VERSION ""

NS_ :

BS_:

BU_: XXX

BO_ 35 EPS_1: 8 XXX
 SG_ STEER_ANGLE : 7|16@0+ (0.5,-2048) [0|65535] "degs" XXX
 SG_ TORQUE_MOTOR : 23|16@0+ (1,-4096) [0|65535] "" XXX
 SG_ COUNTER : 55|4@0+ (1,0) [0|15] "" XXX
 SG_ CHECKSUM : 63|8@0+ (1,0) [0|255] "" XXX

BO_ 37 PCM_1: 8 XXX
 SG_ ENGINE_RPM : 7|16@0+ (1,0) [0|1] "" XXX
 SG_ ENGINE_TRQ_REQ : 23|12@0+ (1,0) [0|1] "" XXX
 SG_ COUNTER : 55|4@0+ (1,0) [0|15] "" XXX
 SG_ CHECKSUM : 63|8@0+ (1,0) [0|255] "" XXX

BO_ 49 EPS_2: 8 XXX
 SG_ STEER_RATE_DRIVER : 19|12@0+ (0.125,-256) [0|1] "degs/s" XXX
 SG_ TORQUE_DRIVER : 35|12@0+ (1,-1024) [-1024|1024] "" XXX
 SG_ EPS_STATUS : 39|4@0+ (1,0) [0|15] "" XXX
 SG_ CHECKSUM : 63|8@0+ (1,0) [0|255] "" XXX
 SG_ COUNTER : 55|4@0+ (1,0) [0|15] "" XXX

BO_ 53 PCM_2: 8 XXX
 SG_ ENG_TORQUE_REQ : 3|12@0+ (1,0) [0|7] "" XXX
 SG_ ENG_TORQUE_OUT : 19|12@0+ (1,0) [0|1] "" XXX
 SG_ CHECKSUM : 63|8@0+ (1,0) [0|255] "" XXX
 SG_ COUNTER : 55|4@0+ (1,0) [0|15] "" XXX

BO_ 121 ABS_1: 8 XXX
 SG_ BRK_PRESSURE : 3|12@0+ (1,0) [0|1] "" XXX
 SG_ BRAKE_PEDAL : 19|12@0+ (1,0) [0|1] "" XXX
 SG_ COUNTER : 55|4@0+ (1,0) [0|15] "" XXX
 SG_ CHECKSUM : 63|8@0+ (1,0) [0|255] "" XXX

BO_ 129 TPS_1: 8 XXX
 SG_ THROTTLE_POSITION : 47|8@0+ (0.5,0) [0|255] "%" XXX

BO_ 133 TCM_1: 8 XXX
 SG_ DESIRED_GEAR : 15|4@0+ (1,0) [0|1] "" XXX
 SG_ SHIFT_PENDING : 2|1@0+ (1,0) [0|1] "" XXX
 SG_ SPEED_TURBINE : 27|12@0+ (0.04,0) [0|1] "km/h" XXX
 SG_ ACTUAL_GEAR : 11|4@0+ (1,0) [0|15] "" XXX

BO_ 135 ABS_2: 8 XXX
 SG_ COUNTER : 55|4@0+ (1,0) [0|1] "" XXX
 SG_ CHECKSUM : 63|8@0+ (1,0) [0|1] "" XXX
 SG_ DRIVER_BRAKE : 15|8@0+ (1,0) [0|1] "" XXX

BO_ 139 WHEEL_SPEEDS: 8 XXX
 SG_ WHEEL_SPEED_LR : 3|12@0+ (0.02,0) [0|4095] "" XXX
 SG_ WHEEL_SPEED_RR : 19|12@0+ (0.02,0) [0|4095] "" XXX
 SG_ WHEEL_SPEED_LF : 35|12@0+ (0.02,0) [0|4095] "" XXX
 SG_ WHEEL_SPEED_RF : 51|12@0+ (0.02,0) [0|4095] "" XXX

BO_ 153 FORWARD_CAMERA_ACC: 8 XXX
 SG_ ACC_ENG_TRQ_REQ : 3|8@0+ (1,0) [0|1] "" XXX
 SG_ ACC_GAS_CONTROL : 7|1@0+ (1,0) [0|1] "" XXX
 SG_ ACC_STATUS : 21|2@0+ (1,0) [0|3] "" XXX
 SG_ COUNTER : 55|4@0+ (1,0) [0|15] "" XXX
 SG_ CHECKSUM : 63|8@0+ (1,0) [0|255] "" XXX

BO_ 163 FORWARD_CAMERA_CLUSTER: 8 XXX
 SG_ ACC_SET_SPEED : 31|8@0+ (1,0) [0|255] "km/h" XXX

BO_ 166 FORWARD_CAMERA_LKAS: 8 XXX
 SG_ LKAS_COMMAND : 15|16@0+ (1,-1024) [0|4095] "" XXX
 SG_ LKAS_CONTROL_BIT : 25|1@0+ (1,0) [0|1] "" XXX
 SG_ COUNTER : 55|4@0+ (1,0) [0|15] "" XXX
 SG_ CHECKSUM : 63|8@0+ (1,0) [0|255] "" XXX

BO_ 173 SHIFTER_ASSM: 8 XXX
 SG_ SHIFTER_POSITION : 3|4@0+ (1,0) [0|15] "" XXX
 SG_ COUNTER : 31|4@0+ (1,0) [0|15] "" XXX
 SG_ CHECKSUM : 39|8@0+ (1,0) [0|255] "" XXX

BO_ 177 WHEEL_BUTTONS_CRUISE_CONTROL: 8 XXX
 SG_ CANCEL : 0|1@0+ (1,0) [0|3] "" XXX
 SG_ SET_PLUS : 2|1@0+ (1,0) [0|1] "" XXX
 SG_ SET_MINUS : 3|1@0+ (1,0) [0|3] "" XXX
 SG_ RESUME : 4|1@0+ (1,0) [0|1] "" XXX
 SG_ CRUISE_CONTROL : 6|1@0+ (1,0) [0|1] "" XXX
 SG_ COUNTER : 15|4@0+ (1,0) [0|15] "" XXX
 SG_ CHECKSUM : 23|8@0+ (1,0) [0|255] "" XXX

BO_ 221 CENTER_STACK: 8 XXX
 SG_ TRAC_OFF : 54|1@0+ (1,0) [0|1] "" XXX

BO_ 250 FORWARD_CAMERA_HUD: 8 XXX
 SG_ AUTO_HIGH_BEAM_BIT : 47|1@0+ (1,0) [0|1] "" XXX
 SG_ LKAS_HUD : 11|4@0+ (1,0) [0|15] "" XXX

BO_ 464 OCCUPANT_RESTRAINT_MODULE: 8 XXX
 SG_ DRIVER_SEATBELT_STATUS : 16|1@0+ (1,0) [0|1] "" XXX

BO_ 657 DOORS: 8 XXX
 SG_ DOOR_OPEN_LF : 17|1@0+ (1,0) [0|1] "" XXX
 SG_ DOOR_OPEN_RF : 18|1@1+ (1,0) [0|3] "" XXX
 SG_ DOOR_OPEN_LR : 19|1@0+ (1,0) [0|1] "" XXX
 SG_ DOOR_OPEN_RR : 20|1@0+ (1,0) [0|1] "" XXX

BO_ 792 STEERING_LEVERS: 8 XXX
 SG_ BLINKER_LEFT : 0|1@0+ (1,0) [0|3] "" XXX
 SG_ BLINKER_RIGHT : 1|1@0+ (1,0) [0|1] "" XXX
 SG_ HIGH_BEAM_FLASH : 3|1@0+ (1,0) [0|3] "" XXX
 SG_ AUTO_HIGH_BEAM : 2|1@0+ (1,0) [0|1] "" XXX

BO_ 232 ACC_CAR_DETECTED: 8 XXX

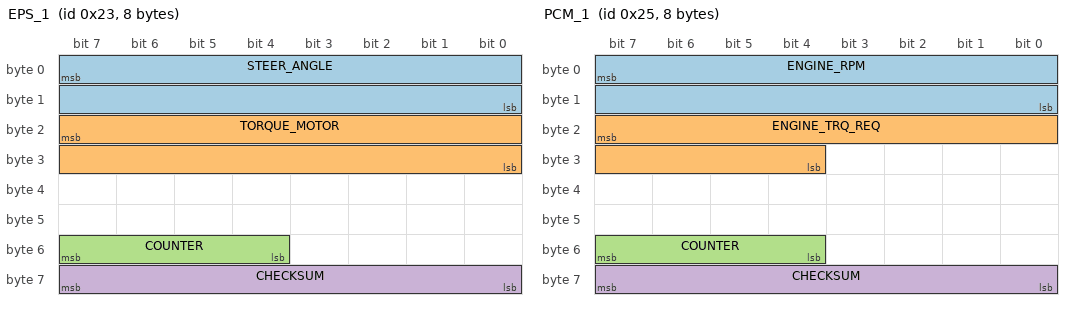
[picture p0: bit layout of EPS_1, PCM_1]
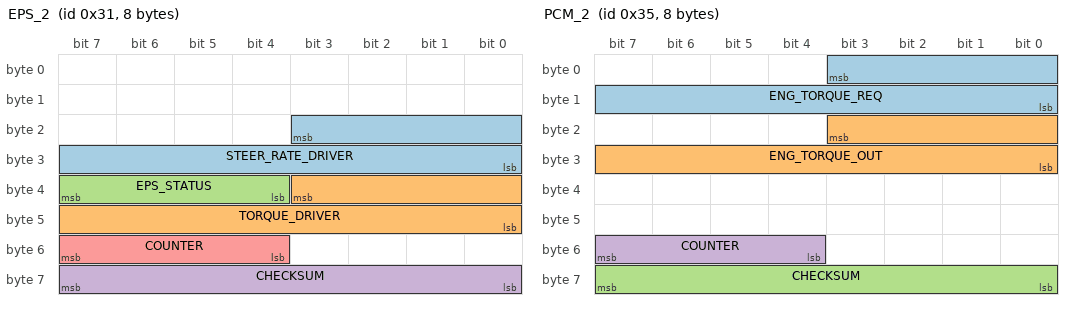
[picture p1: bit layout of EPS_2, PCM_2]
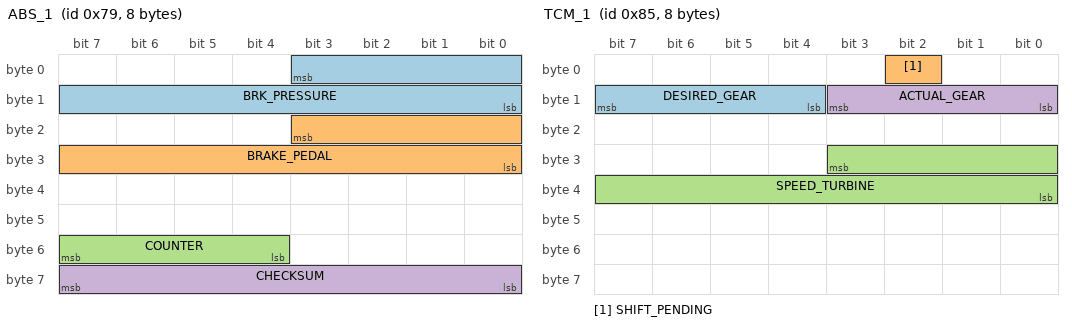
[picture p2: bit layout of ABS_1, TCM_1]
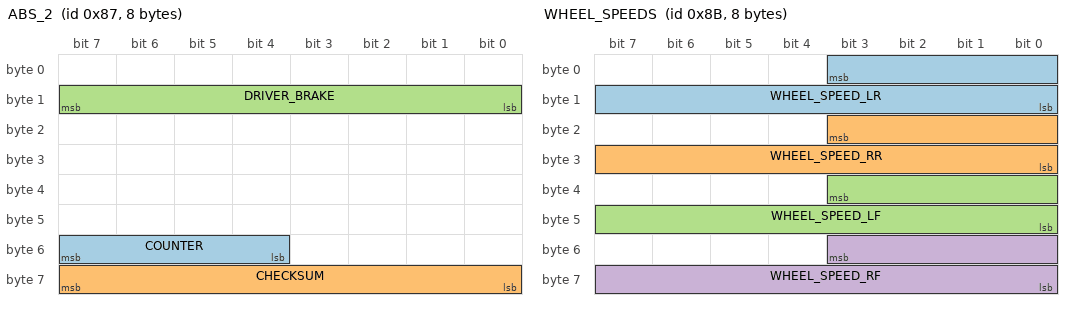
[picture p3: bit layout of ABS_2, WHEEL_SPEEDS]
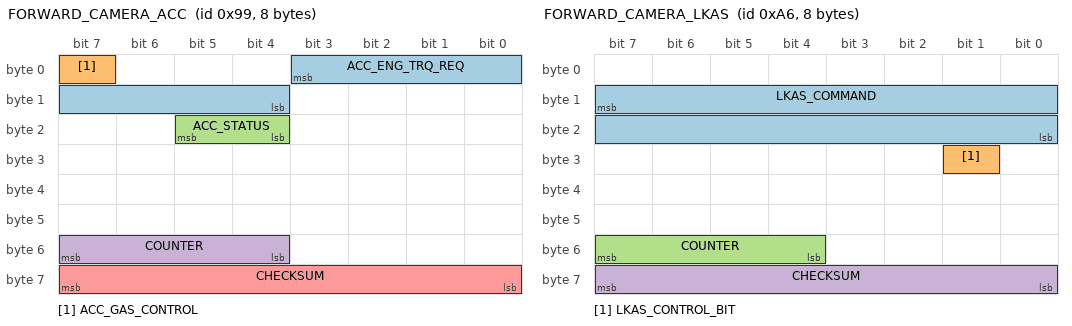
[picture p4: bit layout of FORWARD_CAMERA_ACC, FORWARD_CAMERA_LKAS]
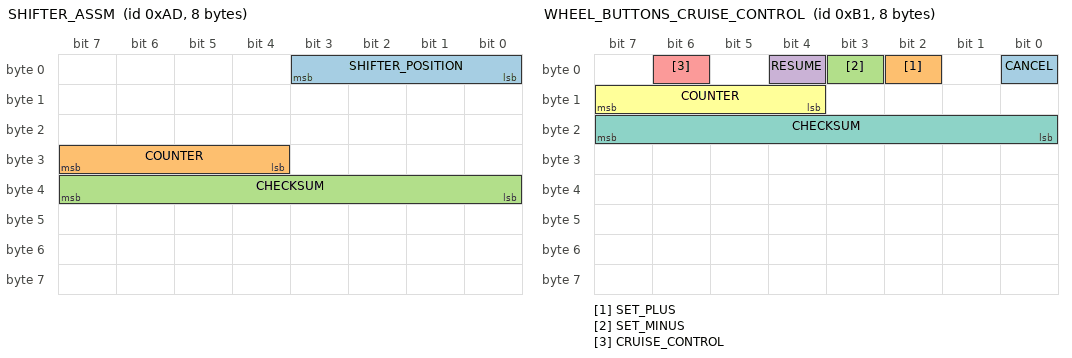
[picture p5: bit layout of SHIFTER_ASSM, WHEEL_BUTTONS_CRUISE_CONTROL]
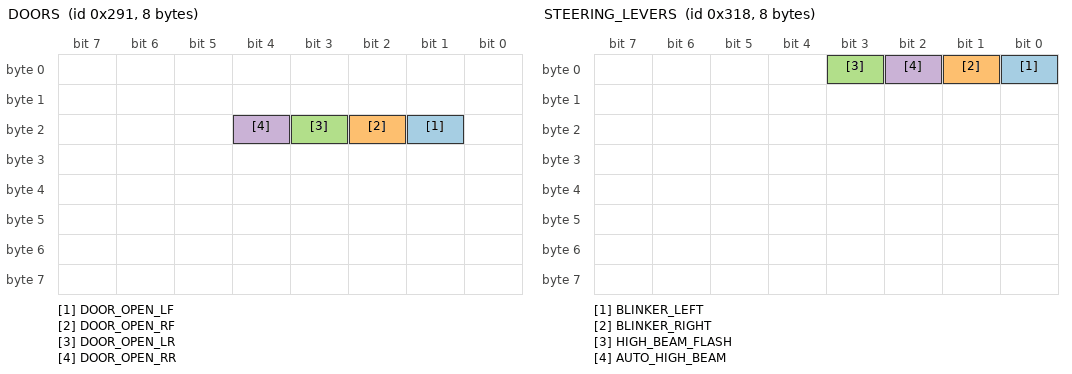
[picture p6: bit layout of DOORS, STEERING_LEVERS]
BO_ 258 EPS_1: 8 XXX
 SG_ NEW_SIGNAL_1 : 23|16@0+ (1,0) [0|65535] "" XXX
 SG_ STEER_ANGLE : 7|16@0+ (1,0) [0|65535] "" XXX

BO_ 280 NEW_MSG_1: 8 XXX

BO_ 264 PCM: 8 XXX
 SG_ RPM : 7|16@0+ (1,0) [0|65535] "" XXX
 SG_ NEW_SIGNAL_1 : 23|12@0+ (1,0) [0|1] "" XXX

CM_ SG_ 35 STEER_ANGLE "540 deg total negative values indicate right turn, positive values indicate left turn";
CM_ SG_ 49 STEER_RATE_DRIVER "seems right";
CM_ SG_ 129 THROTTLE_POSITION "gas pressed when values > 0 ";
CM_ SG_ 133 ACTUAL_GEAR "0xd = P, 0x1-8 = D (actual gear), 0xb = R or N?? TODO find R vs N";
CM_ SG_ 153 ACC_GAS_CONTROL "1 = ACC is doing gas, 0 = human";
CM_ SG_ 153 ACC_STATUS "SENT BY FORWARD CAMERA 1 = ACTIVE, 3 = ENGAGED, 0 = DISENGAGED/OFF";
CM_ SG_ 166 LKAS_COMMAND "SENT BY FORWARD CAMERA";
CM_ SG_ 166 LKAS_CONTROL_BIT "appears to be the lkas takeover indicator";
CM_ SG_ 173 SHIFTER_POSITION "1 = P, 4 = D, 2 = R, 3 = N";
CM_ SG_ 250 AUTO_HIGH_BEAM_BIT "1 = HIGH BEAMS OK 0 = HIGH BEAMS OFF ";
CM_ SG_ 250 LKAS_HUD "9 = LEFT CAUTION, 11 = VERY LEFT CAUTION 10 = RIGHT CAUTION, 14 = VERY RIGHT, 4 = NO LINES DETECTED, 3 = LINES DETECTED, SYSTEM ACTIVE";
CM_ SG_ 464 DRIVER_SEATBELT_STATUS "1 unbuckled 0 buckled";
CM_ SG_ 792 HIGH_BEAM_FLASH "1 is high beam, 0 reg";
CM_ SG_ 792 AUTO_HIGH_BEAM "1 is auto high beams, 0 no high beams";
VAL_ 173 SHIFTER_POSITION 4 "D" 3 "N" 2 "R" 1 "P" ;
